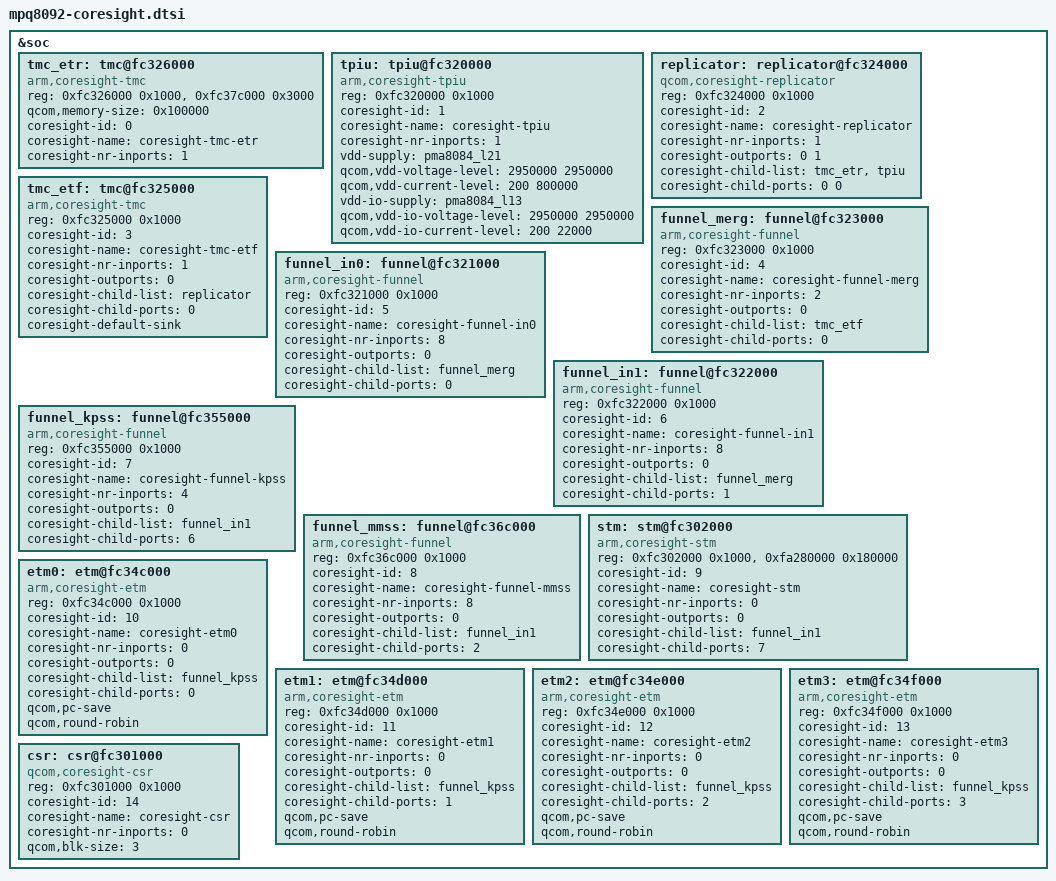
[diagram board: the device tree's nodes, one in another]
/* Copyright (c) 2013, The Linux Foundation. All rights reserved.
 *
 * This program is free software; you can redistribute it and/or modify
 * it under the terms of the GNU General Public License version 2 and
 * only version 2 as published by the Free Software Foundation.
 *
 * This program is distributed in the hope that it will be useful,
 * but WITHOUT ANY WARRANTY; without even the implied warranty of
 * MERCHANTABILITY or FITNESS FOR A PARTICULAR PURPOSE.  See the
 * GNU General Public License for more details.
 */

&soc {
	tmc_etr: tmc@fc326000 {
		compatible = "arm,coresight-tmc";
		reg = <0xfc326000 0x1000>,
		      <0xfc37c000 0x3000>;
		reg-names = "tmc-base", "bam-base";

		qcom,memory-size = <0x100000>;

		coresight-id = <0>;
		coresight-name = "coresight-tmc-etr";
		coresight-nr-inports = <1>;
	};

	tpiu: tpiu@fc320000 {
		compatible = "arm,coresight-tpiu";
		reg = <0xfc320000 0x1000>;
		reg-names = "tpiu-base";

		coresight-id = <1>;
		coresight-name = "coresight-tpiu";
		coresight-nr-inports = <1>;

		vdd-supply = <&pma8084_l21>;

		qcom,vdd-voltage-level = <2950000 2950000>;
		qcom,vdd-current-level = <200 800000>;

		vdd-io-supply = <&pma8084_l13>;

		qcom,vdd-io-voltage-level = <2950000 2950000>;
		qcom,vdd-io-current-level = <200 22000>;
	};

	replicator: replicator@fc324000 {
		compatible = "qcom,coresight-replicator";
		reg = <0xfc324000 0x1000>;
		reg-names = "replicator-base";

		coresight-id = <2>;
		coresight-name = "coresight-replicator";
		coresight-nr-inports = <1>;
		coresight-outports = <0 1>;
		coresight-child-list = <&tmc_etr &tpiu>;
		coresight-child-ports = <0 0>;
	};

	tmc_etf: tmc@fc325000 {
		compatible = "arm,coresight-tmc";
		reg = <0xfc325000 0x1000>;
		reg-names = "tmc-base";

		coresight-id = <3>;
		coresight-name = "coresight-tmc-etf";
		coresight-nr-inports = <1>;
		coresight-outports = <0>;
		coresight-child-list = <&replicator>;
		coresight-child-ports = <0>;
		coresight-default-sink;
	};

	funnel_merg: funnel@fc323000 {
		compatible = "arm,coresight-funnel";
		reg = <0xfc323000 0x1000>;
		reg-names = "funnel-base";

		coresight-id = <4>;
		coresight-name = "coresight-funnel-merg";
		coresight-nr-inports = <2>;
		coresight-outports = <0>;
		coresight-child-list = <&tmc_etf>;
		coresight-child-ports = <0>;
	};

	funnel_in0: funnel@fc321000 {
		compatible = "arm,coresight-funnel";
		reg = <0xfc321000 0x1000>;
		reg-names = "funnel-base";

		coresight-id = <5>;
		coresight-name = "coresight-funnel-in0";
		coresight-nr-inports = <8>;
		coresight-outports = <0>;
		coresight-child-list = <&funnel_merg>;
		coresight-child-ports = <0>;
	};

	funnel_in1: funnel@fc322000 {
		compatible = "arm,coresight-funnel";
		reg = <0xfc322000 0x1000>;
		reg-names = "funnel-base";

		coresight-id = <6>;
		coresight-name = "coresight-funnel-in1";
		coresight-nr-inports = <8>;
		coresight-outports = <0>;
		coresight-child-list = <&funnel_merg>;
		coresight-child-ports = <1>;
	};

	funnel_kpss: funnel@fc355000 {
		compatible = "arm,coresight-funnel";
		reg = <0xfc355000 0x1000>;
		reg-names = "funnel-base";

		coresight-id = <7>;
		coresight-name = "coresight-funnel-kpss";
		coresight-nr-inports = <4>;
		coresight-outports = <0>;
		coresight-child-list = <&funnel_in1>;
		coresight-child-ports = <6>;
	};

	funnel_mmss: funnel@fc36c000 {
		compatible = "arm,coresight-funnel";
		reg = <0xfc36c000 0x1000>;
		reg-names = "funnel-base";

		coresight-id = <8>;
		coresight-name = "coresight-funnel-mmss";
		coresight-nr-inports = <8>;
		coresight-outports = <0>;
		coresight-child-list = <&funnel_in1>;
		coresight-child-ports = <2>;
	};

	stm: stm@fc302000 {
		compatible = "arm,coresight-stm";
		reg = <0xfc302000 0x1000>,
		      <0xfa280000 0x180000>;
		reg-names = "stm-base", "stm-data-base";

		coresight-id = <9>;
		coresight-name = "coresight-stm";
		coresight-nr-inports = <0>;
		coresight-outports = <0>;
		coresight-child-list = <&funnel_in1>;
		coresight-child-ports = <7>;
	};

	etm0: etm@fc34c000 {
                compatible = "arm,coresight-etm";
                reg = <0xfc34c000 0x1000>;
                reg-names = "etm-base";

                coresight-id = <10>;
                coresight-name = "coresight-etm0";
                coresight-nr-inports = <0>;
                coresight-outports = <0>;
                coresight-child-list = <&funnel_kpss>;
                coresight-child-ports = <0>;

                qcom,pc-save;
                qcom,round-robin;
        };

        etm1: etm@fc34d000 {
                compatible = "arm,coresight-etm";
                reg = <0xfc34d000 0x1000>;
                reg-names = "etm-base";

                coresight-id = <11>;
                coresight-name = "coresight-etm1";
                coresight-nr-inports = <0>;
                coresight-outports = <0>;
                coresight-child-list = <&funnel_kpss>;
                coresight-child-ports = <1>;

                qcom,pc-save;
                qcom,round-robin;
        };

        etm2: etm@fc34e000 {
                compatible = "arm,coresight-etm";
                reg = <0xfc34e000 0x1000>;
                reg-names = "etm-base";

                coresight-id = <12>;
                coresight-name = "coresight-etm2";
                coresight-nr-inports = <0>;
                coresight-outports = <0>;
                coresight-child-list = <&funnel_kpss>;
                coresight-child-ports = <2>;

                qcom,pc-save;
                qcom,round-robin;
        };

	etm3: etm@fc34f000 {
                compatible = "arm,coresight-etm";
                reg = <0xfc34f000 0x1000>;
                reg-names = "etm-base";

                coresight-id = <13>;
                coresight-name = "coresight-etm3";
                coresight-nr-inports = <0>;
                coresight-outports = <0>;
                coresight-child-list = <&funnel_kpss>;
                coresight-child-ports = <3>;

                qcom,pc-save;
                qcom,round-robin;
        };

	csr: csr@fc301000 {
		compatible = "qcom,coresight-csr";
		reg = <0xfc301000 0x1000>;
		reg-names = "csr-base";

		coresight-id = <14>;
		coresight-name = "coresight-csr";
		coresight-nr-inports = <0>;

		qcom,blk-size = <3>;
	};
};
